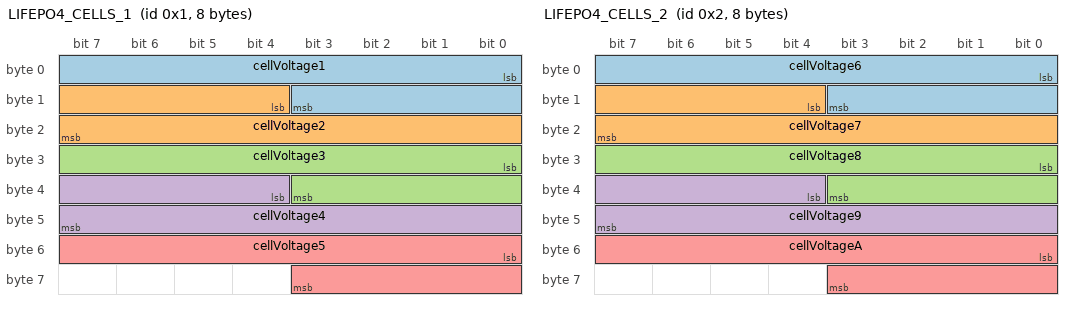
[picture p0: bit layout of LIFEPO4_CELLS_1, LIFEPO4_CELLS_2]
BO_ 1 LIFEPO4_CELLS_1: 8 XXX
 SG_ cellVoltage1 : 0|12@1+ (0.001,0) [0|4] "V" Vector_XXX
 SG_ cellVoltage2 : 12|12@1+ (0.001,0) [0|4] "V" Vector_XXX
 SG_ cellVoltage3 : 24|12@1+ (0.001,0) [0|4] "V" Vector_XXX
 SG_ cellVoltage4 : 36|12@1+ (0.001,0) [0|4] "V" Vector_XXX
 SG_ cellVoltage5 : 48|12@1+ (0.001,0) [0|4] "V" Vector_XXX

BO_ 2 LIFEPO4_CELLS_2: 8 XXX
 SG_ cellVoltage6 : 0|12@1+ (0.001,0) [0|4] "V" Vector_XXX
 SG_ cellVoltage7 : 12|12@1+ (0.001,0) [0|4] "V" Vector_XXX
 SG_ cellVoltage8 : 24|12@1+ (0.001,0) [0|4] "V" Vector_XXX
 SG_ cellVoltage9 : 36|12@1+ (0.001,0) [0|4] "V" Vector_XXX
 SG_ cellVoltageA : 48|12@1+ (0.001,0) [0|4] "V" Vector_XXX

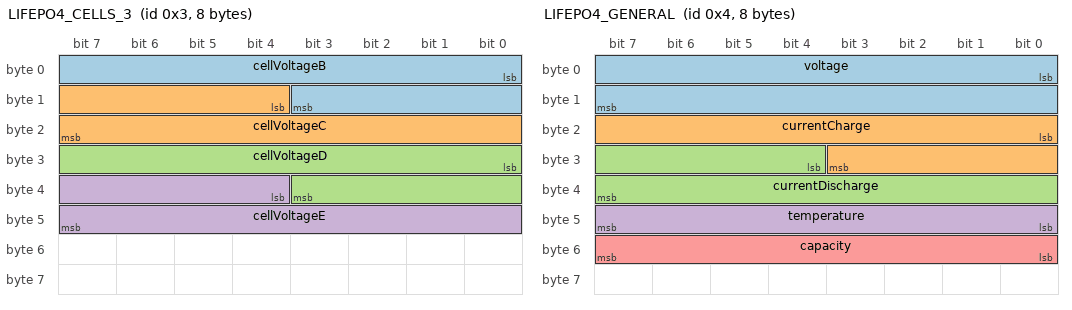
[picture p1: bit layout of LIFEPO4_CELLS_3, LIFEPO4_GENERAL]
BO_ 3 LIFEPO4_CELLS_3: 8 XXX
 SG_ cellVoltageB : 0|12@1+ (0.001,0) [0|4] "V" Vector_XXX
 SG_ cellVoltageC : 12|12@1+ (0.001,0) [0|4] "V" Vector_XXX
 SG_ cellVoltageD : 24|12@1+ (0.001,0) [0|4] "V" Vector_XXX
 SG_ cellVoltageE : 36|12@1+ (0.001,0) [0|4] "V" Vector_XXX

BO_ 4 LIFEPO4_GENERAL: 8 XXX
 SG_ voltage : 0|16@1+ (0.001,0) [0|50] "V" Vector_XXX
 SG_ currentCharge : 16|12@1+ (0.1,0) [0|200] "A" Vector_XXX
 SG_ currentDischarge : 28|12@1+ (0.1,0) [0|200] "A" Vector_XXX
 SG_ temperature : 40|8@1+ (1,0) [0|100] "Celcius" Vector_XXX
 SG_ capacity : 48|8@1+ (1,0) [0|100] "Percent" Vector_XXX

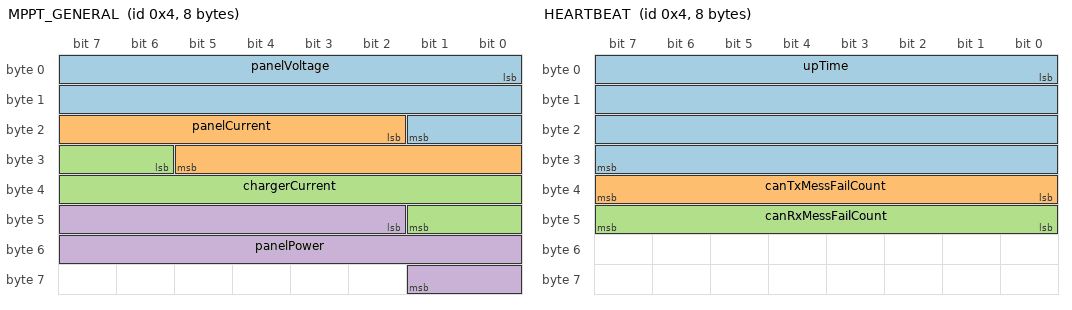
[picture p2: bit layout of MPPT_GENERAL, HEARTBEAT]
BO_ 4 MPPT_GENERAL: 8 XXX
 SG_ panelVoltage : 0|18@1+ (0.001,0) [0|100] "V" Vector_XXX
 SG_ panelCurrent : 18|12@1+ (0.1,0) [0|200] "A" Vector_XXX
 SG_ chargerCurrent : 30|12@1+ (0.1,0) [0|200] "A" Vector_XXX
 SG_ panelPower : 42|16@1+ (0.1,0) [0|500] "W" Vector_XXX

BO_ 4 HEARTBEAT: 8 XXX
 SG_ upTime : 0|32@1+ (0.001,0) [0|4294967296] "s" Vector_XXX
 SG_ canTxMessFailCount : 32|8@1+ (1,0) [0|255] "" Vector_XXX
 SG_ canRxMessFailCount : 40|8@1+ (1,0) [0|255] "" Vector_XXX
